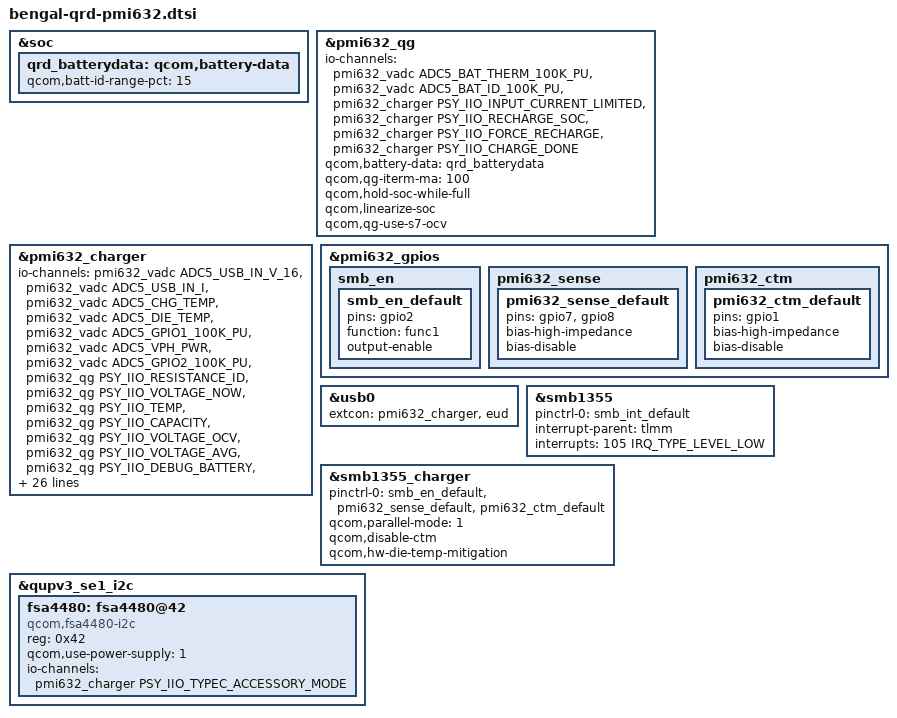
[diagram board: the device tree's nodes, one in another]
#include "bengal-pmi632.dtsi"
#include <dt-bindings/iio/qti_power_supply_iio.h>

&soc {
	qrd_batterydata: qcom,battery-data {
		qcom,batt-id-range-pct = <15>;
		#include "qg-batterydata-atl466271_3300mAh.dtsi"
	};
};

&pmi632_qg {
	status = "ok";
	#io-channel-cells = <1>;
	io-channels = <&pmi632_vadc ADC5_BAT_THERM_100K_PU>,
		      <&pmi632_vadc ADC5_BAT_ID_100K_PU>,
		      <&pmi632_charger PSY_IIO_INPUT_CURRENT_LIMITED>,
		      <&pmi632_charger PSY_IIO_RECHARGE_SOC>,
		      <&pmi632_charger PSY_IIO_FORCE_RECHARGE>,
		      <&pmi632_charger PSY_IIO_CHARGE_DONE>;
	io-channel-names = "batt-therm",
			   "batt-id",
			   "input_current_limited",
			   "recharge_soc",
			   "force_recharge",
			   "charge_done";
	qcom,battery-data = <&qrd_batterydata>;
	qcom,qg-iterm-ma = <100>;
	qcom,hold-soc-while-full;
	qcom,linearize-soc;
	qcom,qg-use-s7-ocv;
};

&pmi632_charger {
	status = "ok";
	#io-channel-cells = <1>;
	io-channels = <&pmi632_vadc ADC5_USB_IN_V_16>,
		      <&pmi632_vadc ADC5_USB_IN_I>,
		      <&pmi632_vadc ADC5_CHG_TEMP>,
		      <&pmi632_vadc ADC5_DIE_TEMP>,
		      <&pmi632_vadc ADC5_GPIO1_100K_PU>,
		      <&pmi632_vadc ADC5_VPH_PWR>,
		      <&pmi632_vadc ADC5_GPIO2_100K_PU>,
		      <&pmi632_qg PSY_IIO_RESISTANCE_ID>,
		      <&pmi632_qg PSY_IIO_VOLTAGE_NOW>,
		      <&pmi632_qg PSY_IIO_TEMP>,
		      <&pmi632_qg PSY_IIO_CAPACITY>,
		      <&pmi632_qg PSY_IIO_VOLTAGE_OCV>,
		      <&pmi632_qg PSY_IIO_VOLTAGE_AVG>,
		      <&pmi632_qg PSY_IIO_DEBUG_BATTERY>,
		      <&pmi632_qg PSY_IIO_REAL_CAPACITY>,
		      <&pmi632_qg PSY_IIO_CC_SOC>,
		      <&pmi632_qg PSY_IIO_CURRENT_NOW>,
		      <&pmi632_qg PSY_IIO_VOLTAGE_MAX>,
		      <&pmi632_qg PSY_IIO_CHARGE_FULL>,
		      <&pmi632_qg PSY_IIO_CHARGE_COUNTER>,
		      <&pmi632_qg PSY_IIO_CYCLE_COUNT>,
		      <&pmi632_qg PSY_IIO_CHARGE_FULL_DESIGN>,
		      <&pmi632_qg PSY_IIO_TIME_TO_FULL_NOW>;
	io-channel-names = "usb_in_voltage",
			   "usb_in_current",
			   "chg_temp",
			   "die_temp",
			   "conn_temp",
			   "vph_voltage",
			   "skin_temp",
			   "resistance_id",
			   "voltage_now",
			   "temp",
			   "capacity",
			   "voltage_ocv",
			   "voltage_avg",
			   "debug_battery",
			   "real_capacity",
			   "cc_soc",
			   "current_now",
			   "voltage_max",
			   "charge_full",
			   "charge_counter",
			   "cycle_count",
			   "charge_full_design",
			   "time_to_full_now";
	qcom,battery-data = <&qrd_batterydata>;
	qcom,suspend-input-on-debug-batt;
	qcom,sw-jeita-enable;
	qcom,step-charging-enable;
	/* SMB1355 only */
	qcom,sec-charger-config = <2>;
	qcom,hvdcp2-max-icl-ua = <2000000>;
	dpdm-supply = <&qusb_phy0>;
	qcom,charger-temp-max = <800>;
	qcom,smb-temp-max = <800>;
	qcom,auto-recharge-soc = <98>;
	qcom,flash-disable-soc = <10>;
	qcom,hw-die-temp-mitigation;
	qcom,hw-connector-mitigation;
	qcom,connector-internal-pull-kohm = <100>;
	qcom,float-option = <1>;
	qcom,thermal-mitigation = <4200000 3500000 3000000
			2500000 2000000 1500000 1000000 500000>;
};

&pmi632_gpios {
	smb_en {
		smb_en_default: smb_en_default {
			pins = "gpio2";
			function = "func1";
			output-enable;
		};
	};

	pmi632_sense {
		/* GPIO 7 and 8 are external-sense pins for PMI632 */
		pmi632_sense_default: pmi632_sense_default {
			pins = "gpio7", "gpio8";
			bias-high-impedance;	/* disable the GPIO */
			bias-disable;		/* no-pull */
		};
	};

	pmi632_ctm {
		/* Disable GPIO1 for h/w base mitigation */
		pmi632_ctm_default: pmi632_ctm_default {
			pins = "gpio1";
			bias-high-impedance;	/* disable the GPIO */
			bias-disable;		/* no-pull */
		};
	};
};

&usb0 {
	extcon = <&pmi632_charger>, <&eud>;
};

&smb1355 {
	pinctrl-names = "default";
	pinctrl-0 = <&smb_int_default>;
	interrupt-parent = <&tlmm>;
	interrupts = <105 IRQ_TYPE_LEVEL_LOW>;
	status = "ok";
};

&smb1355_charger {
	pinctrl-names = "default";
	pinctrl-0 = <&smb_en_default &pmi632_sense_default &pmi632_ctm_default>;
	qcom,parallel-mode = <1>;
	qcom,disable-ctm;
	qcom,hw-die-temp-mitigation;
	status = "ok";
};

&qupv3_se1_i2c {
	fsa4480: fsa4480@42 {
		compatible = "qcom,fsa4480-i2c";
		reg = <0x42>;
		qcom,use-power-supply = <1>;
		#io-channel-cells = <1>;
		io-channels = <&pmi632_charger PSY_IIO_TYPEC_ACCESSORY_MODE>;
		io-channel-names = "typec_mode";
	};
};
